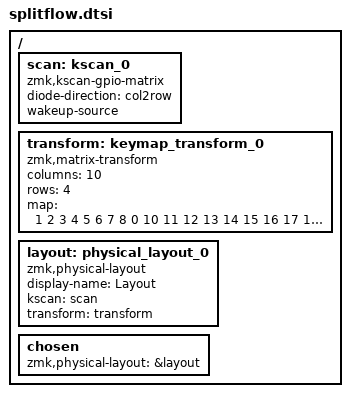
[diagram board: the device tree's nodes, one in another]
/ {

  scan: kscan_0 {
    compatible = "zmk,kscan-gpio-matrix";
    diode-direction = "col2row";
    wakeup-source;
  };

  transform: keymap_transform_0 {
    compatible = "zmk,matrix-transform";
    columns = <10>;
    rows = <4>;

      map = <
        1 2 3 4 5 6 7 8
        0 10 11 12 13 14 15 16 17 18 19 9
        20 21 22 23 24 25 26 27 28 29
        30 31 32 35 36 37
      >;
  };

  layout: physical_layout_0 {
    compatible = "zmk,physical-layout";
    display-name = "Layout";
    kscan = <&scan>;
    transform = <&transform>;
  };

  chosen {
    zmk,physical-layout = &layout;
  };

};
